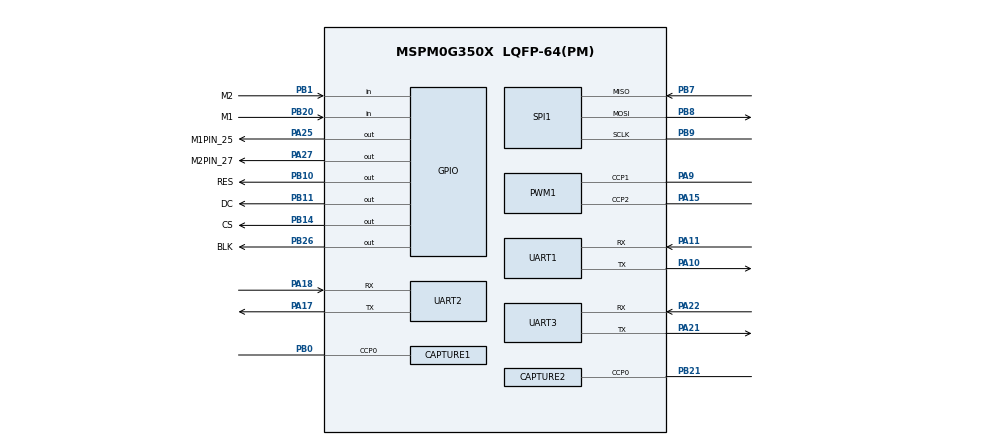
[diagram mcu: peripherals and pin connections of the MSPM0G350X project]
/**
 * @cliArgs --device "MSPM0G350X" --part "Default" --package "LQFP-64(PM)" --product "mspm0_sdk@2.02.00.05"
 * @versions {"tool":"1.21.1+3772"}
 */

/**
 * Import the modules used in this configuration.
 */
const CAPTURE  = scripting.addModule("/ti/driverlib/CAPTURE", {}, false);
const CAPTURE1 = CAPTURE.addInstance();
const CAPTURE2 = CAPTURE.addInstance();
const GPIO     = scripting.addModule("/ti/driverlib/GPIO", {}, false);
const GPIO1    = GPIO.addInstance();
const GPIO2    = GPIO.addInstance();
const GPIO3    = GPIO.addInstance();
const GPIO4    = GPIO.addInstance();
const NONMAIN  = scripting.addModule("/ti/driverlib/NONMAIN");
const PWM      = scripting.addModule("/ti/driverlib/PWM", {}, false);
const PWM1     = PWM.addInstance();
const SPI      = scripting.addModule("/ti/driverlib/SPI", {}, false);
const SPI1     = SPI.addInstance();
const SYSCTL   = scripting.addModule("/ti/driverlib/SYSCTL");
const TIMER    = scripting.addModule("/ti/driverlib/TIMER", {}, false);
const TIMER1   = TIMER.addInstance();
const TIMER2   = TIMER.addInstance();
const UART     = scripting.addModule("/ti/driverlib/UART", {}, false);
const UART1    = UART.addInstance();
const UART2    = UART.addInstance();
const UART3    = UART.addInstance();

/**
 * Write custom configuration values to the imported modules.
 */
const divider6       = system.clockTree["PLL_CLK2X_DIV"];
divider6.divideValue = 4;

const divider7       = system.clockTree["PLL_PDIV"];
divider7.divideValue = 2;

const divider9       = system.clockTree["UDIV"];
divider9.divideValue = 2;

const gate7  = system.clockTree["MFCLKGATE"];
gate7.enable = true;

const gate8  = system.clockTree["MFPCLKGATE"];
gate8.enable = true;

const multiplier2         = system.clockTree["PLL_QDIV"];
multiplier2.multiplyValue = 10;

const mux8       = system.clockTree["HSCLKMUX"];
mux8.inputSelect = "HSCLKMUX_SYSPLL2X";

CAPTURE1.$name                              = "ENCAM1";
CAPTURE1.timerPeriod                        = "1ms";
CAPTURE1.timerClkPrescale                   = 2;
CAPTURE1.interrupts                         = ["CC0_DN"];
CAPTURE1.interruptPriority                  = "3";
CAPTURE1.peripheral.ccp0Pin.$assign         = "PB0";
CAPTURE1.ccp0PinConfig.hideOutputInversion  = scripting.forceWrite(false);
CAPTURE1.ccp0PinConfig.onlyInternalResistor = scripting.forceWrite(false);
CAPTURE1.ccp0PinConfig.passedPeripheralType = scripting.forceWrite("Digital");
CAPTURE1.ccp0PinConfig.$name                = "ti_driverlib_gpio_GPIOPinGeneric5";

const Board = scripting.addModule("/ti/driverlib/Board", {}, false);

CAPTURE2.$name                              = "ENCAM2";
CAPTURE2.timerPeriod                        = "1ms";
CAPTURE2.timerClkPrescale                   = 2;
CAPTURE2.interrupts                         = ["CC0_DN"];
CAPTURE2.interruptPriority                  = "3";
CAPTURE2.peripheral.ccp0Pin.$assign         = "PB21";
CAPTURE2.ccp0PinConfig.hideOutputInversion  = scripting.forceWrite(false);
CAPTURE2.ccp0PinConfig.onlyInternalResistor = scripting.forceWrite(false);
CAPTURE2.ccp0PinConfig.passedPeripheralType = scripting.forceWrite("Digital");
CAPTURE2.ccp0PinConfig.$name                = "ti_driverlib_gpio_GPIOPinGeneric6";

GPIO1.$name                         = "LCD";
GPIO1.port                          = "PORTB";
GPIO1.associatedPins.create(4);
GPIO1.associatedPins[0].$name       = "RES";
GPIO1.associatedPins[0].ioStructure = "SD";
GPIO1.associatedPins[0].assignedPin = "10";
GPIO1.associatedPins[0].pin.$assign = "PB10";
GPIO1.associatedPins[1].$name       = "DC";
GPIO1.associatedPins[1].ioStructure = "SD";
GPIO1.associatedPins[1].assignedPin = "11";
GPIO1.associatedPins[1].pin.$assign = "PB11";
GPIO1.associatedPins[2].$name       = "CS";
GPIO1.associatedPins[2].ioStructure = "SD";
GPIO1.associatedPins[2].assignedPin = "14";
GPIO1.associatedPins[2].pin.$assign = "PB14";
GPIO1.associatedPins[3].$name       = "BLK";
GPIO1.associatedPins[3].assignedPin = "26";
GPIO1.associatedPins[3].ioStructure = "SD";
GPIO1.associatedPins[3].pin.$assign = "PB26";

GPIO2.$name                              = "ENC_B";
GPIO2.port                               = "PORTB";
GPIO2.associatedPins.create(2);
GPIO2.associatedPins[0].$name            = "M1";
GPIO2.associatedPins[0].direction        = "INPUT";
GPIO2.associatedPins[0].assignedPin      = "20";
GPIO2.associatedPins[0].internalResistor = "PULL_UP";
GPIO2.associatedPins[0].pin.$assign      = "PB20";
GPIO2.associatedPins[1].$name            = "M2";
GPIO2.associatedPins[1].direction        = "INPUT";
GPIO2.associatedPins[1].assignedPin      = "1";
GPIO2.associatedPins[1].internalResistor = "PULL_UP";
GPIO2.associatedPins[1].pin.$assign      = "PB1";

GPIO3.$name                          = "Motor1";
GPIO3.associatedPins[0].$name        = "M1PIN_25";
GPIO3.associatedPins[0].assignedPort = "PORTA";
GPIO3.associatedPins[0].assignedPin  = "25";
GPIO3.associatedPins[0].pin.$assign  = "PA25";

GPIO4.$name                          = "Motor2";
GPIO4.associatedPins[0].$name        = "M2PIN_27";
GPIO4.associatedPins[0].assignedPort = "PORTA";
GPIO4.associatedPins[0].assignedPin  = "27";
GPIO4.associatedPins[0].pin.$assign  = "PA27";

NONMAIN.nonmainWarning = true;
NONMAIN.bslMode        = false;

PWM1.$name                              = "MotorPWM";
PWM1.clockDivider                       = 8;
PWM1.pwmMode                            = "EDGE_ALIGN_UP";
PWM1.ccIndex                            = [1,2];
PWM1.timerCount                         = 500;
PWM1.peripheral.ccp1Pin.$assign         = "PA9";
PWM1.peripheral.ccp2Pin.$assign         = "PA15";
PWM1.ccp1PinConfig.direction            = scripting.forceWrite("OUTPUT");
PWM1.ccp1PinConfig.hideOutputInversion  = scripting.forceWrite(false);
PWM1.ccp1PinConfig.onlyInternalResistor = scripting.forceWrite(false);
PWM1.ccp1PinConfig.passedPeripheralType = scripting.forceWrite("Digital");
PWM1.ccp1PinConfig.$name                = "ti_driverlib_gpio_GPIOPinGeneric8";
PWM1.PWM_CHANNEL_2.$name                = "ti_driverlib_pwm_PWMTimerCC2";
PWM1.ccp2PinConfig.$name                = "ti_driverlib_gpio_GPIOPinGeneric9";
PWM1.PWM_CHANNEL_1.$name                = "ti_driverlib_pwm_PWMTimerCC0";

SPI1.$name                              = "SPI_LCD";
SPI1.targetBitRate                      = 2000000;
SPI1.frameFormat                        = "MOTO3";
SPI1.peripheral.$assign                 = "SPI1";
SPI1.peripheral.sclkPin.$assign         = "PB9";
SPI1.peripheral.mosiPin.$assign         = "PB8";
SPI1.peripheral.misoPin.$assign         = "PB7";
SPI1.sclkPinConfig.direction            = scripting.forceWrite("OUTPUT");
SPI1.sclkPinConfig.onlyInternalResistor = scripting.forceWrite(false);
SPI1.sclkPinConfig.passedPeripheralType = scripting.forceWrite("Digital");
SPI1.sclkPinConfig.$name                = "ti_driverlib_gpio_GPIOPinGeneric2";
SPI1.mosiPinConfig.direction            = scripting.forceWrite("OUTPUT");
SPI1.mosiPinConfig.hideOutputInversion  = scripting.forceWrite(false);
SPI1.mosiPinConfig.onlyInternalResistor = scripting.forceWrite(false);
SPI1.mosiPinConfig.passedPeripheralType = scripting.forceWrite("Digital");
SPI1.mosiPinConfig.$name                = "ti_driverlib_gpio_GPIOPinGeneric3";
SPI1.misoPinConfig.onlyInternalResistor = scripting.forceWrite(false);
SPI1.misoPinConfig.passedPeripheralType = scripting.forceWrite("Digital");
SPI1.misoPinConfig.$name                = "ti_driverlib_gpio_GPIOPinGeneric4";

SYSCTL.forceDefaultClkConfig = true;
SYSCTL.clockTreeEn           = true;

TIMER1.$name            = "TIMER_0";
TIMER1.timerClkPrescale = 100;
TIMER1.timerMode        = "PERIODIC";
TIMER1.timerStartTimer  = true;
TIMER1.interrupts       = ["ZERO"];
TIMER1.timerClkDiv      = 2;
TIMER1.timerPeriod      = "10ms";

TIMER2.$name            = "TIMER_1";
TIMER2.timerPeriod      = "10 ms";
TIMER2.timerClkPrescale = 2;
TIMER2.timerClkDiv      = 4;
TIMER2.interrupts       = ["ZERO"];
TIMER2.timerStartTimer  = true;
TIMER2.timerMode        = "PERIODIC";

UART1.$name                    = "UART_0";
UART1.uartClkSrc               = "MFCLK";
UART1.enabledInterrupts        = ["RX"];
UART1.targetBaudRate           = 115200;
UART1.peripheral.rxPin.$assign = "PA11";
UART1.peripheral.txPin.$assign = "PA10";
UART1.txPinConfig.$name        = "ti_driverlib_gpio_GPIOPinGeneric0";
UART1.rxPinConfig.$name        = "ti_driverlib_gpio_GPIOPinGeneric1";

UART2.$name                    = "UART_1";
UART2.uartClkSrc               = "MFCLK";
UART2.enabledInterrupts        = ["RX"];
UART2.peripheral.$assign       = "UART1";
UART2.peripheral.rxPin.$assign = "PA18";
UART2.peripheral.txPin.$assign = "PA17";
UART2.txPinConfig.$name        = "ti_driverlib_gpio_GPIOPinGeneric7";
UART2.rxPinConfig.$name        = "ti_driverlib_gpio_GPIOPinGeneric10";

UART3.$name                    = "UART_2";
UART3.uartClkSrc               = "MFCLK";
UART3.targetBaudRate           = 9600;
UART3.enabledInterrupts        = ["RX"];
UART3.peripheral.$assign       = "UART2";
UART3.peripheral.rxPin.$assign = "PA22";
UART3.peripheral.txPin.$assign = "PA21";

/**
 * Pinmux solution for unlocked pins/peripherals. This ensures that minor changes to the automatic solver in a future
 * version of the tool will not impact the pinmux you originally saw.  These lines can be completely deleted in order to
 * re-solve from scratch.
 */
CAPTURE1.peripheral.$suggestSolution       = "TIMA1";
Board.peripheral.$suggestSolution          = "DEBUGSS";
Board.peripheral.swclkPin.$suggestSolution = "PA20";
Board.peripheral.swdioPin.$suggestSolution = "PA19";
CAPTURE2.peripheral.$suggestSolution       = "TIMG8";
PWM1.peripheral.$suggestSolution           = "TIMA0";
TIMER1.peripheral.$suggestSolution         = "TIMG6";
TIMER2.peripheral.$suggestSolution         = "TIMG0";
UART1.peripheral.$suggestSolution          = "UART0";
UART3.peripheral.$suggestSolution          = "UART2";
